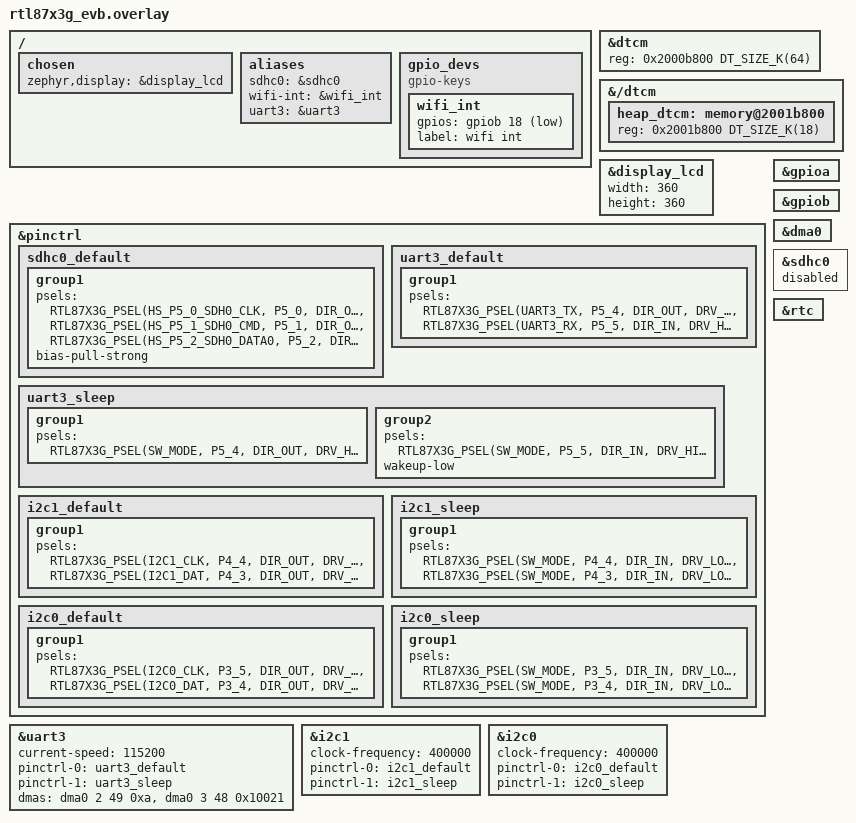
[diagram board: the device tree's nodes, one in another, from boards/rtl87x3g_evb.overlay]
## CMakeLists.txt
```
# SPDX-License-Identifier: Apache-2.0

cmake_minimum_required(VERSION 3.20.0)

#===========version generation===========
include(${CMAKE_CURRENT_SOURCE_DIR}/../../cmake/version_generate.cmake)
generate_version()
#===========version generation===========
#===========post build===========
# post build should be called before find_package
include(${CMAKE_CURRENT_SOURCE_DIR}/../../cmake/post_build.cmake)
# Extract bank name from snippet list (e.g. "flash_16M_bank0" -> "bank0") so
# `west build --snippet flash_16M_bank0/bank1` outputs to bin/<bank>/  (mirrors sample/ota).
set(RTK_BANK "")
foreach(snippet ${SNIPPET})
    if(snippet MATCHES "bank[0-9]+")
        string(REGEX MATCH "bank[0-9]+" RTK_BANK "${snippet}")
        break()
    endif()
endforeach()
if(RTK_BANK)
    # bank build -> bin/<bank>/app_<bank>.bin (+ _MP.bin)
    rtk_post_build(APP_NAME app BANK ${RTK_BANK})
else()
    # default (no snippet) -> bin/app.bin, unchanged
    rtk_post_build()
endif()
#===========post build===========

# FlashDB is pulled in as a West project; its module.yml declares kconfig-ext: True,
# so Zephyr automatically generates osource "$(ZEPHYR_FLASHDB_KCONFIG)".
# Point that variable at the empty Kconfig inside this application to avoid build errors.
set(ZEPHYR_FLASHDB_KCONFIG ${CMAKE_CURRENT_SOURCE_DIR}/port/flashdb/Kconfig)

find_package(Zephyr REQUIRED HINTS $ENV{ZEPHYR_BASE})
project(deskmate)

target_link_libraries(app PRIVATE realtek_display_driver_library)
target_link_libraries(app PRIVATE guiLib)

zephyr_compile_options(
    -Wno-unused-variable
    -Wno-maybe-uninitialized
    -Wno-double-promotion
    -Wno-stringop-truncation
    -Wno-unused-function
    -Wno-missing-braces
    -Wno-use-after-free
    -Wno-parentheses
    -Wno-address
    -Wno-format-overflow
    -Wno-overflow
    -Wno-char-subscripts
    -Wno-enum-compare
)

set(APP_TARGET_NAME app)

if(1) #set to 1 to enable or variable to for depnedency

    file(GLOB SOURCES "*.c" "*.cpp")
    file(GLOB HEADERS "*.h" "*.hpp")


    # Determine if we should create a library
    if((NOT HEADERS) AND (NOT SOURCES))
        message(STATUS "No source or header files found in ${CMAKE_CURRENT_SOURCE_DIR}.")
		target_include_directories(${APP_TARGET_NAME} PUBLIC ${CMAKE_CURRENT_SOURCE_DIR})
    endif()

    if(HEADERS AND (NOT SOURCES))
        target_include_directories(${APP_TARGET_NAME} PUBLIC ${CMAKE_CURRENT_SOURCE_DIR})
    endif()

    if(SOURCES AND (NOT HEADERS))
        target_sources(${APP_TARGET_NAME} PRIVATE ${SOURCES})
    endif()

    if(SOURCES AND HEADERS)
        target_sources(${APP_TARGET_NAME} PRIVATE ${SOURCES})
        target_include_directories(${APP_TARGET_NAME} PUBLIC ${CMAKE_CURRENT_SOURCE_DIR})
    endif()

    # Process subdirectories regardless
    file(GLOB SUBDIRS RELATIVE ${CMAKE_CURRENT_SOURCE_DIR} ${CMAKE_CURRENT_SOURCE_DIR}/*)

    foreach(subdir ${SUBDIRS})
        if(IS_DIRECTORY ${CMAKE_CURRENT_SOURCE_DIR}/${subdir})
            if(EXISTS ${CMAKE_CURRENT_SOURCE_DIR}/${subdir}/CMakeLists.txt)
                add_subdirectory(${subdir})
            else()
                message(STATUS "Skipping directory ${subdir} as it does not contain a CMakeLists.txt file.")
            endif()
        endif()
    endforeach()
endif()
```

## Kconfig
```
# Copyright (c) 2024, Realtek Semiconductor Corporation.
# SPDX-License-Identifier: Apache-2.0

menu "DeskMate Application"

config RTK_BT_BREDR
	bool "Enable Classic Bluetooth (BR/EDR) support"
	default n
	select REALTEK_SUBSYS_BTM
	select REALTEK_SUBSYS_SYSM
	select REALTEK_SUBSYS_REMOTE
	help
	  Enable Realtek Classic Bluetooth BR/EDR stack.
	  Activates BTM, SYSM, and Remote subsystems.

config RTK_BR_PROFILE_A2DP
	bool "Enable A2DP profile (Sink + Source)"
	depends on RTK_BT_BREDR
	default n

config RTK_BR_PROFILE_AVRCP
	bool "Enable AVRCP profile (CT + TG)"
	depends on RTK_BT_BREDR
	default n

config RTK_BR_PROFILE_HFP
	bool "Enable HFP profile (HF + AG)"
	depends on RTK_BT_BREDR
	default n

config RTK_BR_PROFILE_PAN
	bool "Enable PAN profile (PANU + NAP)"
	depends on RTK_BT_BREDR
	default n

config REALTEK_BUILD_EXAMPLE_EBADGE
    bool "Ebadge Widget Demo"
	default n

config HIGH_LEVEL_BOARD
    bool "High Level Board"
	default n

# External 8711 Wi-Fi chip over SPI: the WIFI_8711 switch app/protocol guards on,
# plus the AT-over-SPI transport it selects.  Turned on by the wifi snippet, which
# also carries the devicetree nodes the module binds to.
#
# One rsource where there were two.  The other was app/wifi_8711/Kconfig, the SPI
# SLAVE stack against custom 8711 firmware; that module is gone and WIFI_8711 moved
# in beside the transport it now selects.
rsource "app/spi_at_master/Kconfig"

endmenu

menu "Zephyr Kernel"
source "Kconfig.zephyr"
endmenu
```

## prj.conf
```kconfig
# App and platform logs use trace.h; do not enable the Zephyr LOG subsystem.
CONFIG_LOG=n
CONFIG_REALTEK_SUBSYS_BLE_MGR=y
CONFIG_RTK_BT_BREDR=y
CONFIG_DFU_NORMAL_OTA=y
CONFIG_RTK_BR_PROFILE_A2DP=y
CONFIG_RTK_BR_PROFILE_AVRCP=y
CONFIG_RTK_BR_PROFILE_HFP=y
CONFIG_REALTEK_SUBSYS_AUDIO=y
# PAN pulls in the IP stack and is unrelated to HFP/A2DP. The additional
# profile does not fit in the watch application partition with DSP enabled.
CONFIG_RTK_BR_PROFILE_PAN=n
CONFIG_SERIAL=y
CONFIG_CONSOLE=n
CONFIG_UART_CONSOLE=n
CONFIG_SHELL=n
CONFIG_SHELL_BACKEND_SERIAL=n
#start display config
CONFIG_REALTEK_HONEYGUI=y
# No current watch page uses H.264. Keeping the decoder linked leaves no room
# for the audio stack in the 1.5 MiB application partition.
CONFIG_REALTEK_H264_DECODER=n
CONFIG_REALTEK_H264BSD=n
# CONFIG_REALTEK_BUILD_EXAMPLE_IMAGE_WIDGET=y
# The Designer-generated smartwatch UI replaces the Real Canvas demo.
# Both use GUI_INIT_APP_EXPORT(app_init); enabling both at once redefines __honeygui_init_app_init.
CONFIG_REALTEK_BUILD_REAL_CANVAS=n
# CONFIG_REALTEK_BUILD_REAL_EARTH_3D=y

# HoneyGUI 2.x defaults optional widgets to y. The watch UI only uses the
# core, view, canvas, geometry, list, image and text widgets. Linking the
# remaining widgets overflows the watch application partition.
CONFIG_REALTEK_GUI_WIDGET_SVG=n
CONFIG_REALTEK_GUI_WIDGET_GIF=n
CONFIG_REALTEK_GUI_WIDGET_GLASS=n
CONFIG_REALTEK_GUI_WIDGET_VIDEO=n
CONFIG_REALTEK_GUI_WIDGET_LITE_VIDEO=n
CONFIG_REALTEK_GUI_WIDGET_STREAM=n
CONFIG_REALTEK_GUI_WIDGET_QBCODE=n
CONFIG_REALTEK_GUI_WIDGET_SOCCER=n
CONFIG_REALTEK_GUI_WIDGET_CARD_LIST=n
CONFIG_REALTEK_GUI_WIDGET_MENU_CELLULAR=n
# Console and log output remain enabled. HoneyGUI's separate letter-shell is
# not referenced by the generated watch UI and only consumes application
# partition space. The generated view headers include gui_list.h, so the list
# and canvas widgets remain enabled.
CONFIG_REALTEK_BUILD_LETTER_SHELL=n

CONFIG_DISPLAY=y
CONFIG_REALTEK_DISPLAY=y
CONFIG_REALTEK_DISPLAY_ENABLE_LCDC=y
CONFIG_REALTEK_DISPLAY_ENABLE_PPE=y
CONFIG_REALTEK_DISPLAY_ENABLE_IDU=y
CONFIG_REALTEK_DISPLAY_GUI_ACC=y
CONFIG_REALTEK_DISPLAY_ENABLE_JPU=y

# CONFIG_REALTEK_LCD_ST77916_360_360_QSPI is not set
CONFIG_REALTEK_LCD_AUTO_360_360_QSPI=y
CONFIG_REALTEK_TOUCH_CHSC6417_ZEPHYR=n
CONFIG_REALTEK_KEY_BUTTON_8773G_ZEPHYR=n
CONFIG_GPIO=y
CONFIG_GPIO_ENABLE_DISABLE_INTERRUPT=y
CONFIG_I2C=y
CONFIG_CPP=y
CONFIG_REQUIRES_FULL_LIBCPP=y
CONFIG_NEWLIB_LIBC=y
#start display config
CONFIG_SIZE_OPTIMIZATIONS_AGGRESSIVE=y
CONFIG_UART_ASYNC_API=y
CONFIG_SDHC=n
CONFIG_SDIO_STACK=n
CONFIG_HEAP_MEM_POOL_SIZE=2048
CONFIG_OSIF_TASK_MAX_COUNT=12

CONFIG_CBPRINTF_FP_SUPPORT=n
# The new upstream display/HoneyGUI code needs a smaller stack footprint to
# keep the fixed RAM region within budget. The main work still runs in the
# application and Bluetooth task stacks.
CONFIG_MAIN_STACK_SIZE=4096
CONFIG_IDLE_STACK_SIZE=1024
CONFIG_SYSTEM_WORKQUEUE_STACK_SIZE=768

# RTC (posix /dev/rtc0 + editor-level features)
CONFIG_RTC=y
CONFIG_RTC_RTL87X3G=y
CONFIG_RTC_ALARM=y
CONFIG_RTC_UPDATE=y
```

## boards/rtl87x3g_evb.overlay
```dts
/*
 * Copyright (c) 2024, Realtek Semiconductor Corporation. All rights reserved.
 */

#include <zephyr/dt-bindings/pinctrl/rtl87x3g-pinctrl.h>
#include <zephyr/dt-bindings/gpio/realtek-rtl87x3g-gpio.h>
#include <rtl87x3g-display-lcd.dtsi>

/ {
	chosen {
		zephyr,display = &display_lcd;
	};

};

/* HealthAlgorithm adds about 3 KiB of static RAM. Move 4 KiB from the
 * separate DTCM heap into the linked DTCM region. */
&dtcm {
	reg = <0x2000b800 DT_SIZE_K(64)>;
};

&{/dtcm} {
	/delete-node/ memory@2001a800;

	heap_dtcm: memory@2001b800 {
		device_type = "heap dtcm region";
		reg = <0x2001b800 DT_SIZE_K(18)>;
	};
};

&display_lcd {
	status = "okay";
	/* ST77916 360x360 QSPI: override dtsi default (480x272) */
	width = <360>;
	height = <360>;
};

&pinctrl {
	sdhc0_default: sdhc0_default {
		group1 {
			psels =
				<RTL87X3G_PSEL(HS_P5_0_SDH0_CLK,   P5_0, DIR_OUT, DRV_HIGH, PULL_UP)>,
				<RTL87X3G_PSEL(HS_P5_1_SDH0_CMD,   P5_1, DIR_OUT, DRV_HIGH, PULL_UP)>,
				<RTL87X3G_PSEL(HS_P5_2_SDH0_DATA0, P5_2, DIR_OUT, DRV_HIGH, PULL_UP)>;
			bias-pull-strong;
		};
	};

	uart3_default: uart3_default {
		group1 {
			psels =
				<RTL87X3G_PSEL(UART3_TX, P5_4, DIR_OUT, DRV_HIGH, PULL_UP)>,
				<RTL87X3G_PSEL(UART3_RX, P5_5, DIR_IN,  DRV_HIGH, PULL_UP)>;
		};
	};
	uart3_sleep: uart3_sleep {
		group1 {
			psels = <RTL87X3G_PSEL(SW_MODE, P5_4, DIR_OUT, DRV_HIGH, PULL_UP)>;
		};
		group2 {
			psels = <RTL87X3G_PSEL(SW_MODE, P5_5, DIR_IN, DRV_HIGH, PULL_UP)>;
			wakeup-low;
		};
	};

	i2c1_default: i2c1_default {
		group1 {
			psels =
				<RTL87X3G_PSEL(I2C1_CLK, P4_4, DIR_OUT, DRV_HIGH, PULL_NONE)>,
				<RTL87X3G_PSEL(I2C1_DAT, P4_3, DIR_OUT, DRV_HIGH, PULL_NONE)>;
		};
	};
	i2c1_sleep: i2c1_sleep {
		group1 {
			psels =
				<RTL87X3G_PSEL(SW_MODE, P4_4, DIR_IN, DRV_LOW, PULL_UP)>,
				<RTL87X3G_PSEL(SW_MODE, P4_3, DIR_IN, DRV_LOW, PULL_UP)>;
		};
	};

	/* I2C0 (Gsensor): SCL=P3_5, SDA=P3_4 */
	i2c0_default: i2c0_default {
		group1 {
			psels =
				<RTL87X3G_PSEL(I2C0_CLK, P3_5, DIR_OUT, DRV_HIGH, PULL_NONE)>,
				<RTL87X3G_PSEL(I2C0_DAT, P3_4, DIR_OUT, DRV_HIGH, PULL_NONE)>;
		};
	};
	i2c0_sleep: i2c0_sleep {
		group1 {
			psels =
				<RTL87X3G_PSEL(SW_MODE, P3_5, DIR_IN, DRV_LOW, PULL_UP)>,
				<RTL87X3G_PSEL(SW_MODE, P3_4, DIR_IN, DRV_LOW, PULL_UP)>;
		};
	};
};

&gpioa {
	status = "okay";
};

&gpiob {
	status = "okay";
};

&uart3 {
	status = "okay";
	current-speed = <115200>;
	pinctrl-0 = <&uart3_default>;
	pinctrl-1 = <&uart3_sleep>;
	pinctrl-names = "default", "sleep";
	dmas = <&dma0 2 49 0xa>, <&dma0 3 48 0x10021>;
	dma-names = "rx", "tx";
};

&dma0 {
	status = "okay";
};

&sdhc0 {
	/* MOY.M81023.01 has no SD socket. P5_0/P5_1/P5_2 are the display
	 * backlight, sensor rail enable and LCD reset controls instead. */
	status = "disabled";
};

/ {
	aliases {
		sdhc0 = &sdhc0;
		wifi-int = &wifi_int;
		uart3 = &uart3;
	};
	gpio_devs {
		compatible = "gpio-keys";
		wifi_int: wifi_int {
			gpios = <&gpiob 18 GPIO_ACTIVE_LOW>;  /* P5_3 */
			label = "wifi int";
		};
	};

};

&i2c1 {
	status = "okay";
	clock-frequency = <400000>;
	pinctrl-0 = <&i2c1_default>;
	pinctrl-1 = <&i2c1_sleep>;
	pinctrl-names = "default", "sleep";
};

&i2c0 {
	status = "okay";
	clock-frequency = <400000>;
	pinctrl-0 = <&i2c0_default>;
	pinctrl-1 = <&i2c0_sleep>;
	pinctrl-names = "default", "sleep";
};

&rtc {
	status = "okay";
};
```

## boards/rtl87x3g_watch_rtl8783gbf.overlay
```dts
#include <zephyr/dt-bindings/gpio/realtek-rtl87x3g-gpio.h>
#include <dt-bindings/pinctrl/rtl87x3g-pinctrl.h>

&uart3 {
	pinctrl-0 = <&uart3_default>;
	pinctrl-1 = <&uart3_sleep>;
	pinctrl-names = "default", "sleep";
	status = "okay";
	current-speed = <115200>;
	parity = "none";
	stop-bits = "1";
	data-bits = <8>;
	dmas = <&dma0 2 49 0xa>, <&dma0 3 48 0x10021>;
	dma-names = "rx", "tx";
};

&pinctrl {
	uart3_default: uart3_default {
		group1 {
			psels = <RTL87X3G_PSEL(UART3_TX, UART3_TX_PIN, DIR_OUT, DRV_HIGH, PULL_UP)>,
				<RTL87X3G_PSEL(UART3_RX, UART3_RX_PIN, DIR_IN, DRV_HIGH, PULL_UP)>,
				<RTL87X3G_PSEL(SW_MODE, UART3_MP_TX_PIN, DIR_OUT, DRV_HIGH, PULL_UP)>,
				<RTL87X3G_PSEL(SW_MODE, UART3_MP_RX_PIN, DIR_IN, DRV_HIGH, PULL_UP)>;
		};
	};

	uart3_mp: uart3_mp {
		group1 {
			psels = <RTL87X3G_PSEL(SW_MODE, UART3_TX_PIN, DIR_OUT, DRV_HIGH, PULL_UP)>,
				<RTL87X3G_PSEL(SW_MODE, UART3_RX_PIN, DIR_IN, DRV_HIGH, PULL_UP)>,
				<RTL87X3G_PSEL(UART3_TX, UART3_MP_TX_PIN, DIR_OUT, DRV_HIGH, PULL_UP)>,
				<RTL87X3G_PSEL(UART3_RX, UART3_MP_RX_PIN, DIR_IN, DRV_HIGH, PULL_UP)>;
		};
	};

	uart3_sleep: uart3_sleep {
		group1 {
			psels = <RTL87X3G_PSEL(SW_MODE, UART3_TX_PIN, DIR_OUT, DRV_HIGH, PULL_UP)>,
				<RTL87X3G_PSEL(SW_MODE, UART3_MP_TX_PIN, DIR_OUT, DRV_HIGH, PULL_UP)>;
		};

		group2 {
			psels = <RTL87X3G_PSEL(SW_MODE, UART3_RX_PIN, DIR_IN, DRV_HIGH, PULL_UP)>,
				<RTL87X3G_PSEL(SW_MODE, UART3_MP_RX_PIN, DIR_IN, DRV_HIGH, PULL_UP)>;
			wakeup-low;
		};
	};
};

/ {
	aliases {
		sdhc0 = &sdhc0;
		uart3 = &uart3;
		wifi-int = &wifi_int;
	};

	zephyr,user {
		uart3_mp_pin = <&uart3_mp>;
	};

	gpio_devs {
		compatible = "gpio-keys";

		wifi_int: wifi_int {
			gpios = <WIFI_INT_GPIO_PIN GPIO_ACTIVE_LOW>;
			label = "wifi int";
		};
	};
};
```

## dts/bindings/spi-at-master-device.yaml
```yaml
#
# Copyright (c) 2026, Realtek Semiconductor Corporation
#
# SPDX-License-Identifier: LicenseRef-Realtek-5-Clause
#

description: |
    The RTL8711FA as a slave device on our SPI bus.

    This child node exists only in the master configuration.  As slave we had no
    bus peer to describe, so the wifi_8711 overlay put status="okay" on
    spi0_slave and stopped there; as master the peer is a real device and its
    spi-max-frequency is what the controller is programmed to.

    That property is load-bearing rather than documentation: SPI_DT_SPEC_GET
    copies it into spi_config.frequency, and spi_rtl87x3g_configure() rejects
    anything above the parent node's max-bus-freq outright (-EINVAL, not a
    clamp).  25 MHz therefore only works under spi1_hs, which is rated 50 MHz --
    spi0/spi1/spi2 are all rated 20 MHz and would fail at bring-up.

    Consumed by app/spi_at_master/ via DT_NODELABEL(spi_at_master_device).

compatible: "spi-at-master-device"

include: [spi-device.yaml]
```

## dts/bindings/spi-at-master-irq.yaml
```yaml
#
# Copyright (c) 2026, Realtek Semiconductor Corporation
#
# SPDX-License-Identifier: LicenseRef-Realtek-5-Clause
#

description: |
    The two out-of-band handshake GPIOs of the RTL8773G <-> RTL8711FA SPI link
    in its MASTER configuration: we drive SCLK and CS, the 8711 is the slave.

    The pads are the same two the slave build used and their DIRECTIONS ARE
    SWAPPED.  That is the one mistake this binding exists to prevent, because an
    overlay copied from wifi_8711-irq compiles perfectly and then drives the
    wrong line the wrong way, with nothing catching it at build time:

                     wifi_8711-irq (slave)      THIS binding (master)
      P4_1 GPIOB8    b2w, our OUTPUT            s2m, our INPUT
      P2_7 GPIOA22   w2b, our INPUT             m2s, our OUTPUT

    The names are relative to whoever holds the master role, which is now us --
    hence m2s/s2m rather than b2w/w2b.  Do not mix the two vocabularies.

    Handshake, per the vendor reference example/atcmd_host/atcmd_host_spi:

      m2s  master -> slave REQUEST, our output.  Asserted (pad LOW) to tell the
           8711 "prepare to receive"; released (pad HIGH) once the slot has been
           clocked.  It is only a request -- it never starts a transfer by
           itself.
      s2m  slave -> master GO-AHEAD, our interrupt input.  The 8711 raises it
           when its DMA is armed, whether that is in answer to our m2s or
           because it has something of its own to send.  The rising edge is the
           go-ahead for BOTH directions, so it is the only edge we act on and
           the transport blocks on it before every transfer.

    Idle levels, which the polarity flags below must encode:
      m2s idles HIGH, asserted LOW   -> declare it GPIO_ACTIVE_LOW, so
                                        GPIO_OUTPUT_INACTIVE parks the pad high
      s2m idles LOW,  asserted HIGH  -> declare it GPIO_ACTIVE_HIGH

    Consumed by app/spi_at_master/ via DT_NODELABEL(spi_at_master_resources).

compatible: "spi-at-master-irq"

properties:
  m2s-gpios:
    type: phandle-array
    required: true
    description: |
      M2S / REQUEST: 8773 -> 8711, our push-pull output.  Active LOW, idles
      HIGH -- must carry GPIO_ACTIVE_LOW or the line is inverted in silence.
  s2m-gpios:
    type: phandle-array
    required: true
    description: |
      S2M / GO-AHEAD: 8711 -> 8773, our interrupt input.  Active high, idles
      low; a pull-down keeps a floating line from reading as a permanent
      go-ahead before the 8711 powers up.
```

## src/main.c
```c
/**
*********************24, Realtek Semiconductor Corporation. All rights reserved.
*****************************************************************************************
   * @file      main.c
   * @brief     Source file for display project, mainly used for initialize modules
   * @author    Luke
   * @date      2024-08-29
   * @version   v1.0
   **************************************************************************************
   * @attention
   * <h2><center>&copy; COPYRIGHT 2023 Realtek Semiconductor Corporation</center></h2>
   **************************************************************************************
  */

/*============================================================================*
 *                              Header Files
 *============================================================================*/

#include "trace.h"
#include "display_init.h"
#include "os_sched.h"





/* Non-Secure main. */
int main(void)
{
    DBG_DIRECT("Non-Secure World: main");

    display_system_clock_init();
    display_components_init();
    display_task_init();

    /* Start scheduler. */
    os_sched_start();
}
/*-----------------------------------------------------------*/
```

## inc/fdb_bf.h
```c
/*
 * Copyright (c) 2020, Armink, <armink.ztl@gmail.com>
 *
 * SPDX-License-Identifier: Apache-2.0
 */

/**
 * @file
 * @brief Big File (BF) extension public APIs.
 *
 * The Big File extension stores bulk data in a dedicated FAL data partition while
 * keeping a per-file directory entry inside a user-shared KVDB. Each directory
 * entry is a single KV whose name uses the reserved prefix FDB_BF_KEY_PREFIX, so a
 * file commit equals one atomic KV set. The data partition must live on a NOR flash
 * (write granularity == 1 bit) and is managed by a rotating allocator.
 */

#ifndef _FDB_BF_H_
#define _FDB_BF_H_

#include <stdint.h>
#include <stddef.h>
#include <stdbool.h>
#include <fdb_cfg.h>
#include <fdb_def.h>

#ifdef FDB_USING_BF

#ifndef FDB_USING_FAL_MODE
#error "The Big File extension (FDB_USING_BF) requires FDB_USING_FAL_MODE."
#endif

#include <fal.h>

#ifdef __cplusplus
extern "C" {
#endif

/* the reserved KV name prefix used by the directory entries */
#ifndef FDB_BF_KEY_PREFIX
#define FDB_BF_KEY_PREFIX            "bf/"
#endif

/* the max length (including the '\0') of a user file key, excluding the prefix */
#ifndef FDB_BF_KEY_MAX
#define FDB_BF_KEY_MAX               32
#endif

/* the max number of files that can be opened/created at the same time */
#ifndef FDB_BF_MAX_OPEN_HANDLES
#define FDB_BF_MAX_OPEN_HANDLES      4
#endif

/* the max number of files the allocator can track when searching for free space */
#ifndef FDB_BF_MAX_ENTRIES
#define FDB_BF_MAX_ENTRIES           32
#endif

/* directory entry flag bits (32 bit) */
#define FDB_BF_FLAG_CRC_VALID        0x00000001U     /**< data_crc field holds a valid CRC32 of the data */

/**
 * Big File directory entry. Stored as the value of one KVDB KV (24 bytes).
 */
struct fdb_bf_dirent
{
    uint32_t offset;        /**< data offset relative to the data partition start */
    uint32_t capacity;      /**< allocated capacity, aligned to flash block size */
    uint32_t size;          /**< valid data length (<= capacity) */
    uint32_t data_crc;      /**< CRC32 of data range [offset, offset + size), valid when FDB_BF_FLAG_CRC_VALID set */
    uint32_t flags;         /**< flag bits, @see FDB_BF_FLAG_* */
    uint32_t reserved;      /**< reserved for future use, set to 0 */
};
typedef struct fdb_bf_dirent *fdb_bf_dirent_t;

/**
 * Big File open/write handle.
 */
struct fdb_bf_file
{
    struct fdb_bf *db;                 /**< owner BF object */
    bool      in_use;                  /**< handle slot is allocated */
    char      key[FDB_BF_KEY_MAX];     /**< user file key (without prefix) */
    uint32_t  offset;                  /**< data offset in the data partition */
    uint32_t  capacity;                /**< allocated capacity */
    uint32_t  size;                    /**< current valid data length */
};
typedef struct fdb_bf_file *fdb_bf_file_t;

/**
 * Big File database object.
 */
struct fdb_bf
{
    fdb_kvdb_t
    dir_kvdb;                          /**< user-shared KVDB holding the directory entries */
    const struct fal_partition *data_part;         /**< data partition */
    const struct fal_flash_dev *data_flash;        /**< flash device of the data partition */
    uint32_t
    blk_size;                          /**< erase block size of the data flash (allocation unit) */
    uint32_t    data_size;                         /**< data partition length in bytes */
    uint32_t    write_cursor;                      /**< rotating allocation cursor, rebuilt at init */
    struct fdb_bf_file handles[FDB_BF_MAX_OPEN_HANDLES];
    void       *user_data;
    bool        inited;                            /**< initialized successfully */
};
typedef struct fdb_bf *fdb_bf_t;

/**
 * The callback used by fdb_bf_foreach().
 *
 * @param key the user file key (without prefix)
 * @param ent the directory entry
 * @param xip_addr the absolute (memory-mapped/XIP) flash address of the file data
 * @param arg the user argument passed to fdb_bf_foreach()
 *
 * @return return true to stop the iteration, false to continue
 */
typedef bool (*fdb_bf_iter_cb)(const char *key, const struct fdb_bf_dirent *ent, uint32_t xip_addr,
                               void *arg);

/**
 * Big File space usage. Filled in by fdb_bf_space().
 *
 * The allocator only ever hands out a *contiguous* block-aligned run, so
 * `largest_free` -- not `free_size` -- decides whether an fdb_bf_create() of a
 * given size can succeed. The two differ once the partition is fragmented.
 */
struct fdb_bf_space
{
    uint32_t total_size;      /**< data partition length, == db->data_size */
    uint32_t used_size;       /**< sum of every entry's allocated capacity */
    uint32_t free_size;       /**< total_size - used_size, possibly fragmented */
    uint32_t largest_free;    /**< biggest contiguous free run; the usable limit */
    uint32_t valid_size;      /**< sum of every entry's valid data length */
    uint32_t file_count;      /**< number of committed big files */
    uint32_t blk_size;        /**< allocation unit (erase block size) */
    bool     truncated;       /**< true: > FDB_BF_MAX_ENTRIES files, figures are partial */
};

/* lifecycle */
fdb_err_t fdb_bf_init(fdb_bf_t db, fdb_kvdb_t dir_kvdb, const char *data_part_name,
                      void *user_data);
fdb_err_t fdb_bf_deinit(fdb_bf_t db);

/* write: create -> append... -> commit(data_crc) / abort
 *
 * fdb_bf_commit(file, NULL)       -- commit without data CRC
 * fdb_bf_commit(file, &crc_val)   -- commit and store caller-computed CRC32
 *                                    (sets FDB_BF_FLAG_CRC_VALID in flags)
 *
 * The caller is responsible for accumulating the CRC across fdb_bf_append
 * calls using any CRC32 implementation they prefer.
 */
fdb_err_t fdb_bf_create(fdb_bf_t db, const char *key, size_t max_size, fdb_bf_file_t *out);
fdb_err_t fdb_bf_append(fdb_bf_file_t file, const void *buf, size_t len);
fdb_err_t fdb_bf_commit(fdb_bf_file_t file, const uint32_t *data_crc);
fdb_err_t fdb_bf_abort(fdb_bf_file_t file);

/* manage */
fdb_err_t fdb_bf_delete(fdb_bf_t db, const char *key);
fdb_err_t fdb_bf_delete_by_addr(fdb_bf_t db, uint32_t addr);

/**
 * How much of the data partition fdb_bf_reset() erases.
 *
 * This is a choice about ERASE COST, not about correctness: either way every
 * directory entry is dropped, so either way the files are gone and every figure
 * the API reports falls back to empty.  fdb_bf_create() erases each range before
 * it hands it out, so nothing downstream depends on the partition having been
 * pre-erased.
 *
 * Spelled as an enum rather than a bool because `fdb_bf_reset(db, true, &n)` at
 * a call site says nothing about what is true.
 */
typedef enum
{
    /**
     * Drop the directory only.  Milliseconds: one KV delete per file, and a KV
     * delete just flips a status field in place.
     *
     * The old bytes stay on flash until something allocates over them.  They are
     * unreachable through this API -- no entry names them -- but they are still
     * readable by anything that walks the raw partition.
     */
    FDB_BF_RESET_DIR_ONLY = 0,

    /**
     * Also erase the whole data partition, so no remnant of the old files is
     * readable afterwards.
     *
     * SECONDS, and it scales with the partition, not with how much of it is in
     * use: one sector erase per blk_size of the WHOLE partition.  On the eBadge's
     * 5 MB bf_data at 4 KB sectors that is 1280 erases, and it costs the same
     * whether one file was stored or thirty.  Do not put this on a path a user
     * waits on unless the remnants matter.
     */
    FDB_BF_RESET_ERASE_DATA,
} fdb_bf_reset_mode_t;

/**
 * Factory-reset the Big File area: drop every directory entry, and optionally
 * erase the data partition too.
 *
 * Only KVs carrying the reserved FDB_BF_KEY_PREFIX are removed -- the directory
 * KVDB is shared with the application, and its ordinary KVs are left untouched.
 * (This is why fdb_kv_set_default() is NOT the right tool here: it would wipe
 * the application's own settings along with the file directory.)
 *
 * Every "record" a caller can observe -- file_count, used_size, valid_size, the
 * allocator's write cursor -- is *derived* from the directory entries on each
 * query, never stored, so all of them fall back to empty as a consequence of
 * clearing the directory. There is no separate counter to reset.
 *
 * WHICH MODE TO PASS.  FDB_BF_RESET_DIR_ONLY unless you specifically need the old
 * bytes gone: the erase is the entire cost of this call (milliseconds against
 * seconds) and it buys nothing the directory clear has not already bought.  See
 * fdb_bf_reset_mode_t.
 *
 * Order is deliberate when erasing: the directory is cleared *before* the payload.
 * A power loss during the (multi-second) erase then leaves entries gone and data
 * partly erased, which is consistent. The reverse order would leave entries
 * pointing at erased bytes, i.e. files that exist but read as 0xFF.
 *
 * @param db          the BF object
 * @param mode        FDB_BF_RESET_DIR_ONLY or FDB_BF_RESET_ERASE_DATA
 * @param out_removed optional, receives the number of entries deleted; may be
 *                    NULL. It is filled in even when the erase step later fails.
 *
 * @return FDB_NO_ERR on success;
 *         FDB_BUSY if a write session (fdb_bf_create) is still open -- commit or
 *         abort it first, since resetting under it would strand its handle;
 *         FDB_ERASE_ERR if the payload erase failed (directory is already empty,
 *         so the files are gone regardless; only stale bytes survive).
 */
fdb_err_t fdb_bf_reset(fdb_bf_t db, fdb_bf_reset_mode_t mode, uint32_t *out_removed);
bool      fdb_bf_exists(fdb_bf_t db, const char *key);
fdb_err_t fdb_bf_stat(fdb_bf_t db, const char *key, struct fdb_bf_dirent *out);
fdb_err_t fdb_bf_foreach(fdb_bf_t db, fdb_bf_iter_cb cb, void *arg);
fdb_err_t fdb_bf_get_addr(fdb_bf_t db, const char *key, uint32_t *out_addr, size_t *out_size);

/* space accounting
 *
 * fdb_bf_space()      -- full report, one pass over the directory entries
 * fdb_bf_free_size()  -- shorthand for the number that actually gates a create:
 *                        the largest contiguous free run, 0 on error
 */
fdb_err_t fdb_bf_space(fdb_bf_t db, struct fdb_bf_space *out);
uint32_t  fdb_bf_free_size(fdb_bf_t db);

#ifdef __cplusplus
}
#endif

#endif /* FDB_USING_BF */

#endif /* _FDB_BF_H_ */
```

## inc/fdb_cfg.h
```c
/*
 * Copyright (c) 2022, kaans, <https://github.com/kaans>
 *
 * SPDX-License-Identifier: Apache-2.0
 */

/**
 * @file
 * @brief configuration file
 */

#ifndef _FDB_CFG_H_
#define _FDB_CFG_H_

/* using KVDB feature */
#define FDB_USING_KVDB

#ifdef FDB_USING_KVDB
/* Auto update KV to latest default when current KVDB version number is changed. @see fdb_kvdb.ver_num */
/* #define FDB_KV_AUTO_UPDATE */

#define FDB_USING_BF
#endif

/* using TSDB (Time series database) feature */
#define FDB_USING_TSDB

/* Using FAL storage mode */
#define FDB_USING_FAL_MODE

/* the flash write granularity, unit: bit
 * only support 1(nor flash)/ 8(stm32f2/f4)/ 32(stm32f1) */
#define FDB_WRITE_GRAN 1 /* @note you must define it for a value */

/* MCU Endian Configuration, default is Little Endian Order. */
/* #define FDB_BIG_ENDIAN  */

/* log print macro using ESP_LOG.
 * Need to include esp_log.h when setting FDB_PRINT to ESP_LOGI().
 * default EF_PRINT macro is printf() */
//#include <esp_log.h>
//#define FDB_PRINT(...) ESP_LOGI("fdb", __VA_ARGS__)

/* print debug information */
#define FDB_DEBUG_ENABLE

#endif /* _FDB_CFG_H_ */
```

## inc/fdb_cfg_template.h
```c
/*
 * Copyright (c) 2020, Armink, <armink.ztl@gmail.com>
 *
 * SPDX-License-Identifier: Apache-2.0
 */

/**
 * @file
 * @brief configuration template file. You need to rename the file to "fbd_cfg.h" and modify the configuration items in it to suit your use.
 */

#ifndef _FDB_CFG_H_
#define _FDB_CFG_H_

/* using KVDB feature */
#define FDB_USING_KVDB

#ifdef FDB_USING_KVDB
/* Auto update KV to latest default when current KVDB version number is changed. @see fdb_kvdb.ver_num */
/* #define FDB_KV_AUTO_UPDATE */
#endif

/* using TSDB (Time series database) feature */
#define FDB_USING_TSDB

/* Use fixed-size blobs in TSDB to save flash overhead (8 bytes per entry).
 * Define this to the fixed blob size in bytes when all TSL entries are the same size.
 * Ideal for logging fixed-size sensor data (e.g., float + timestamp).
 * Warning: If defined will be incompatible with variable blob flash store or if fixed blob size is later changed */
/* #define FDB_TSDB_FIXED_BLOB_SIZE 4 */

/* Using FAL storage mode */
#define FDB_USING_FAL_MODE

#ifdef FDB_USING_FAL_MODE
/* the flash write granularity, unit: bit
 * only support 1(nor flash)/ 8(stm32f2/f4)/ 32(stm32f1)/ 64(stm32f7)/ 128(stm32h5)/ 256(stm32h7) */
#define FDB_WRITE_GRAN                /* @note you must define it for a value */
#endif

/* Using file storage mode by LIBC file API, like fopen/fread/fwrte/fclose */
/* #define FDB_USING_FILE_LIBC_MODE */

/* Using file storage mode by POSIX file API, like open/read/write/close */
/* #define FDB_USING_FILE_POSIX_MODE */

/* Using the Big File (BF) extension.
 * Requires FDB_USING_FAL_MODE and a NOR flash data partition (write_gran == 1).
 * A user-shared KVDB holds 24-byte directory entries under the "bf/" prefix, while
 * bulk data lives in a dedicated FAL partition managed by a rotating allocator. */
/* #define FDB_USING_BF */

#ifdef FDB_USING_BF
/* KV name prefix reserved for Big File directory entries. Default: "bf/" */
/* #define FDB_BF_KEY_PREFIX           "bf/" */

/* max user file key length including the terminating '\0'. Default: 32 */
/* #define FDB_BF_KEY_MAX              32 */

/* max number of concurrently open/writing file handles. Default: 4 */
/* #define FDB_BF_MAX_OPEN_HANDLES     4 */

/* max number of files tracked by the allocator (occupancy table size). Default: 32 */
/* #define FDB_BF_MAX_ENTRIES          32 */
#endif

/* MCU Endian Configuration, default is Little Endian Order. */
/* #define FDB_BIG_ENDIAN */

/* log print macro. default EF_PRINT macro is printf() */
/* #define FDB_PRINT(...)              my_printf(__VA_ARGS__) */

/* print debug information */
#define FDB_DEBUG_ENABLE

#endif /* _FDB_CFG_H_ */
```

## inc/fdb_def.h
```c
/*
 * Copyright (c) 2020-2023, Armink, <armink.ztl@gmail.com>
 *
 * SPDX-License-Identifier: Apache-2.0
 */

/**
 * @file
 * @brief Public definition.
 */

#ifndef _FDB_DEF_H_
#define _FDB_DEF_H_

#ifdef FDB_USING_NATIVE_ASSERT
#include <assert.h>
#endif

#ifdef __cplusplus
extern "C" {
#endif

/* software version number */
#define FDB_SW_VERSION                 "2.2.99"
#define FDB_SW_VERSION_NUM             0x20299

/* the KV max name length must less then it */
#ifndef FDB_KV_NAME_MAX
#define FDB_KV_NAME_MAX                64
#endif

/* the KV cache table size, it will improve KV search speed when using cache */
#ifndef FDB_KV_CACHE_TABLE_SIZE
#define FDB_KV_CACHE_TABLE_SIZE        64
#endif

/* the sector cache table size, it will improve KV save speed when using cache */
#ifndef FDB_SECTOR_CACHE_TABLE_SIZE
#define FDB_SECTOR_CACHE_TABLE_SIZE    8
#endif

#if (FDB_KV_CACHE_TABLE_SIZE > 0) && (FDB_SECTOR_CACHE_TABLE_SIZE > 0)
#define FDB_KV_USING_CACHE
#endif

#if defined(FDB_USING_FILE_LIBC_MODE) || defined(FDB_USING_FILE_POSIX_MODE)
#define FDB_USING_FILE_MODE
#endif

/* the file cache table size, it will improve GC speed in file mode when using cache */
#ifndef FDB_FILE_CACHE_TABLE_SIZE
#define FDB_FILE_CACHE_TABLE_SIZE    2
#endif

#ifndef FDB_WRITE_GRAN
#define FDB_WRITE_GRAN 1
#endif

/* log function. default FDB_PRINT macro is printf() */
#ifndef FDB_PRINT
// #define FDB_PRINT(...)                 printf(__VA_ARGS__)
#define FDB_PRINT(...) 
#endif
#define FDB_LOG_PREFIX1()              FDB_PRINT("[FlashDB]" FDB_LOG_TAG)
#define FDB_LOG_PREFIX2()              FDB_PRINT(" ")
#define FDB_LOG_PREFIX()               FDB_LOG_PREFIX1();FDB_LOG_PREFIX2()
#ifdef FDB_DEBUG_ENABLE
#define FDB_DEBUG(...)                 FDB_LOG_PREFIX();FDB_PRINT("(%s:%d) ", __FILE__, __LINE__);FDB_PRINT(__VA_ARGS__)
#else
#define FDB_DEBUG(...)
#endif
/* routine print function. Must be implement by user. */
#define FDB_INFO(...)                  FDB_LOG_PREFIX();FDB_PRINT(__VA_ARGS__)
/* assert for developer. */
#ifdef FDB_USING_NATIVE_ASSERT
#define FDB_ASSERT(EXPR)               assert(EXPR);
#else
#ifndef FDB_ASSERT
#define FDB_ASSERT(EXPR)                                                      \
if (!(EXPR))                                                                  \
{                                                                             \
    FDB_INFO("(%s) has assert failed at %s.\n", #EXPR, __func__);             \
    while (1);                                                                \
}
#endif /* FDB_ASSERT */
#endif /* FDB_USING_NATIVE_ASSERT */

#define FDB_KVDB_CTRL_SET_SEC_SIZE     0x00             /**< set sector size control command, this change MUST before database initialization */
#define FDB_KVDB_CTRL_GET_SEC_SIZE     0x01             /**< get sector size control command */
#define FDB_KVDB_CTRL_SET_LOCK         0x02             /**< set lock function control command */
#define FDB_KVDB_CTRL_SET_UNLOCK       0x03             /**< set unlock function control command */
#define FDB_KVDB_CTRL_SET_FILE_MODE    0x09             /**< set file mode control command, this change MUST before database initialization */
#define FDB_KVDB_CTRL_SET_MAX_SIZE     0x0A             /**< set database max size in file mode control command, this change MUST before database initialization */
#define FDB_KVDB_CTRL_SET_NOT_FORMAT   0x0B             /**< set database NOT format mode control command, this change MUST before database initialization */
#define FDB_KVDB_CTRL_SET_RESERVED_PREFIX 0x0C          /**< set the reserved KV name prefix; KVs using this prefix are rejected by the public set/del API (used by the Big File extension), this change MUST after database initialization */

#define FDB_TSDB_CTRL_SET_SEC_SIZE     0x00             /**< set sector size control command, this change MUST before database initialization */
#define FDB_TSDB_CTRL_GET_SEC_SIZE     0x01             /**< get sector size control command */
#define FDB_TSDB_CTRL_SET_LOCK         0x02             /**< set lock function control command */
#define FDB_TSDB_CTRL_SET_UNLOCK       0x03             /**< set unlock function control command */
#define FDB_TSDB_CTRL_SET_ROLLOVER     0x04             /**< set rollover control command, this change MUST after database initialization */
#define FDB_TSDB_CTRL_GET_ROLLOVER     0x05             /**< get rollover control command */
#define FDB_TSDB_CTRL_GET_LAST_TIME    0x06             /**< get last save time control command */
#define FDB_TSDB_CTRL_SET_FILE_MODE    0x09             /**< set file mode control command, this change MUST before database initialization */
#define FDB_TSDB_CTRL_SET_MAX_SIZE     0x0A             /**< set database max size in file mode control command, this change MUST before database initialization */
#define FDB_TSDB_CTRL_SET_NOT_FORMAT   0x0B             /**< set database NOT formatable mode control command, this change MUST before database initialization */

#ifdef FDB_USING_TIMESTAMP_64BIT
    typedef int64_t fdb_time_t;
#else
    typedef int32_t fdb_time_t;
#endif /* FDB_USING_TIMESTAMP_64BIT */

typedef fdb_time_t (*fdb_get_time)(void);

struct fdb_default_kv_node {
    char *key;
    void *value;
    size_t value_len;
};

struct fdb_default_kv {
    struct fdb_default_kv_node *kvs;
    size_t num;
};

/* error code */
typedef enum {
    FDB_NO_ERR,
    FDB_ERASE_ERR,
    FDB_READ_ERR,
    FDB_WRITE_ERR,
    FDB_PART_NOT_FOUND,
    FDB_KV_NAME_ERR,
    FDB_KV_NAME_EXIST,
    FDB_SAVED_FULL,
    FDB_INIT_FAILED,
    FDB_NOT_FOUND,                                /**< the target (KV / Big File / address) is not found */
    FDB_NO_SPACE,                                 /**< no enough space for the operation */
    FDB_UNSUPPORTED,                              /**< the operation is not supported on current storage medium */
    FDB_BUSY,                                     /**< no free resource (e.g. Big File open handle) */
    FDB_INVALID_PARAM,                            /**< invalid parameter */
} fdb_err_t;

enum fdb_kv_status {
    FDB_KV_UNUSED,
    FDB_KV_PRE_WRITE,
    FDB_KV_WRITE,
    FDB_KV_PRE_DELETE,
    FDB_KV_DELETED,
    FDB_KV_ERR_HDR,
#define FDB_KV_STATUS_NUM                        6
};
typedef enum fdb_kv_status fdb_kv_status_t;

enum fdb_tsl_status {
    FDB_TSL_UNUSED,
    FDB_TSL_PRE_WRITE,
    FDB_TSL_WRITE,
    FDB_TSL_USER_STATUS1,
    FDB_TSL_DELETED,
    FDB_TSL_USER_STATUS2,
#define FDB_TSL_STATUS_NUM                       6
};
typedef enum fdb_tsl_status fdb_tsl_status_t;

/* key-value node object */
struct fdb_kv {
    fdb_kv_status_t status;                      /**< node status, @see fdb_kv_status_t */
    bool crc_is_ok;                              /**< node CRC32 check is OK */
    uint8_t name_len;                            /**< name length */
    uint32_t magic;                              /**< magic word(`K`, `V`, `4`, `0`) */
    uint32_t len;                                /**< node total length (header + name + value), must align by FDB_WRITE_GRAN */
    uint32_t value_len;                          /**< value length */
    char name[FDB_KV_NAME_MAX];                  /**< name */
    struct {
        uint32_t start;                          /**< node start address */
        uint32_t value;                          /**< value start address */
    } addr;
};
typedef struct fdb_kv *fdb_kv_t;

struct fdb_kv_iterator {
    struct fdb_kv curr_kv;                       /**< Current KV we get from the iterator */
    uint32_t iterated_cnt;                       /**< How many KVs have we iterated already */
    size_t iterated_obj_bytes;                   /**< Total storage size of KVs we have iterated. */
    size_t iterated_value_bytes;                 /**< Total value size of KVs we have iterated. */
    uint32_t sector_addr;                        /**< Current sector address we're iterating. DO NOT touch it. */
    uint32_t traversed_len;                      /**< Traversed sector total length. */
};
typedef struct fdb_kv_iterator *fdb_kv_iterator_t;

/* time series log node object */
struct fdb_tsl {
    fdb_tsl_status_t status;                     /**< node status, @see fdb_log_status_t */
    fdb_time_t time;                             /**< node timestamp */
    uint32_t log_len;                            /**< log length, must align by FDB_WRITE_GRAN */
    struct {
        uint32_t index;                          /**< node index address */
        uint32_t log;                            /**< log data address */
    } addr;
};
typedef struct fdb_tsl *fdb_tsl_t;
typedef bool (*fdb_tsl_cb)(fdb_tsl_t tsl, void *arg);

typedef enum {
    FDB_DB_TYPE_KV,
    FDB_DB_TYPE_TS,
} fdb_db_type;

/* the flash sector store status */
enum fdb_sector_store_status {
    FDB_SECTOR_STORE_UNUSED,
    FDB_SECTOR_STORE_EMPTY,
    FDB_SECTOR_STORE_USING,
    FDB_SECTOR_STORE_FULL,
#define FDB_SECTOR_STORE_STATUS_NUM              4
};
typedef enum fdb_sector_store_status fdb_sector_store_status_t;

/* the flash sector dirty status */
enum fdb_sector_dirty_status {
    FDB_SECTOR_DIRTY_UNUSED,
    FDB_SECTOR_DIRTY_FALSE,
    FDB_SECTOR_DIRTY_TRUE,
    FDB_SECTOR_DIRTY_GC,
#define FDB_SECTOR_DIRTY_STATUS_NUM              4
};
typedef enum fdb_sector_dirty_status fdb_sector_dirty_status_t;

/* KVDB section information */
struct kvdb_sec_info {
    bool check_ok;                               /**< sector header check is OK */
    struct {
        fdb_sector_store_status_t store;         /**< sector store status @see fdb_sector_store_status_t */
        fdb_sector_dirty_status_t dirty;         /**< sector dirty status @see sector_dirty_status_t */
    } status;
    uint32_t addr;                               /**< sector start address */
    uint32_t magic;                              /**< magic word(`E`, `F`, `4`, `0`) */
    uint32_t combined;                           /**< the combined next sector number, 0xFFFFFFFF: not combined */
    size_t remain;                               /**< remain size */
    uint32_t empty_kv;                           /**< the next empty KV node start address */
};
typedef struct kvdb_sec_info *kv_sec_info_t;

/* TSDB section information */
struct tsdb_sec_info {
    bool check_ok;                               /**< sector header check is OK */
    fdb_sector_store_status_t status;            /**< sector store status @see fdb_sector_store_status_t */
    uint32_t addr;                               /**< sector start address */
    uint32_t magic;                              /**< magic word(`T`, `S`, `L`, `0`) */
    fdb_time_t start_time;                       /**< the first start node's timestamp, 0xFFFFFFFF: unused */
    fdb_time_t end_time;                         /**< the last end node's timestamp, 0xFFFFFFFF: unused */
    uint32_t end_idx;                            /**< the last end node's index, 0xFFFFFFFF: unused */
    fdb_tsl_status_t end_info_stat[2];           /**< the last end node's info status */
    size_t remain;                               /**< remain size */
    uint32_t empty_idx;                          /**< the next empty node index address */
    uint32_t empty_data;                         /**< the next empty node's data end address */
};
typedef struct tsdb_sec_info *tsdb_sec_info_t;

struct kv_cache_node {
    uint16_t name_crc;                           /**< KV name's CRC32 low 16bit value */
    uint16_t active;                             /**< KV node access active degree */
    uint32_t addr;                               /**< KV node address */
};
typedef struct kv_cache_node *kv_cache_node_t;

/* database structure */
typedef struct fdb_db *fdb_db_t;
struct fdb_db {
    const char *name;                            /**< database name */
    fdb_db_type type;                            /**< database type */
    union {
#ifdef FDB_USING_FAL_MODE
        const struct fal_partition *part;        /**< flash partition for saving database */
#endif
#ifdef FDB_USING_FILE_MODE
        const char *dir;                         /**< directory path for saving database */
#endif
    } storage;
    uint32_t sec_size;                           /**< flash section size. It's a multiple of block size */
    uint32_t max_size;                           /**< database max size. It's a multiple of section size */
    uint32_t oldest_addr;                        /**< the oldest sector start address */
    bool init_ok;                                /**< initialized successfully */
    bool file_mode;                              /**< is file mode, default is false */
    bool not_formatable;                         /**< is can NOT be formated mode, default is false */
#ifdef FDB_USING_FILE_MODE
    uint32_t cur_file_sec[FDB_FILE_CACHE_TABLE_SIZE];/**< last operate sector address  */
#if defined(FDB_USING_FILE_POSIX_MODE)
    int cur_file[FDB_FILE_CACHE_TABLE_SIZE];     /**< current file object */
#elif defined(FDB_USING_FILE_LIBC_MODE)
    FILE *cur_file[FDB_FILE_CACHE_TABLE_SIZE];   /**< current file object */
#endif /* FDB_USING_FILE_MODE */
    uint32_t cur_sec;                            /**< current operate sector address  */
#endif
    void (*lock)(fdb_db_t db);                   /**< lock the database operate */
    void (*unlock)(fdb_db_t db);                 /**< unlock the database operate */

    void *user_data;
};

/* KVDB structure */
struct fdb_kvdb {
    struct fdb_db parent;                        /**< inherit from fdb_db */
    struct fdb_default_kv default_kvs;           /**< default KV */
    bool gc_request;                             /**< request a GC check */
    bool in_recovery_check;                      /**< is in recovery check status when first reboot */
    struct fdb_kv cur_kv;
    struct kvdb_sec_info cur_sector;
    bool last_is_complete_del;
    const char *reserved_prefix;                 /**< reserved KV name prefix set by FDB_KVDB_CTRL_SET_RESERVED_PREFIX; NULL means no reservation */

#ifdef FDB_KV_USING_CACHE
    /* KV cache table */
    struct kv_cache_node kv_cache_table[FDB_KV_CACHE_TABLE_SIZE];
    /* sector cache table, it caching the sector info which status is current using */
    struct kvdb_sec_info sector_cache_table[FDB_SECTOR_CACHE_TABLE_SIZE];
#endif /* FDB_KV_USING_CACHE */

#ifdef FDB_KV_AUTO_UPDATE
    uint32_t ver_num;                            /**< setting version number for update */
#endif

    void *user_data;
};
typedef struct fdb_kvdb *fdb_kvdb_t;

/* TSDB structure */
struct fdb_tsdb {
    struct fdb_db parent;                        /**< inherit from fdb_db */
    struct tsdb_sec_info cur_sec;                /**< current using sector */
    fdb_time_t last_time;                        /**< last TSL timestamp */
    fdb_get_time get_time;                       /**< the current timestamp get function */
    size_t max_len;                              /**< the maximum length of each log */
    bool rollover;                               /**< the oldest data will rollover by newest data, default is true */

    void *user_data;
};
typedef struct fdb_tsdb *fdb_tsdb_t;

/* blob structure */
struct fdb_blob {
    void *buf;                                   /**< blob data buffer */
    size_t size;                                 /**< blob data buffer size */
    struct {
        uint32_t meta_addr;                      /**< saved KV or TSL index address */
        uint32_t addr;                           /**< blob data saved address */
        size_t len;                              /**< blob data saved length */
    } saved;
};
typedef struct fdb_blob *fdb_blob_t;

#ifdef __cplusplus
}
#endif

#endif /* _FDB_DEF_H_ */
```

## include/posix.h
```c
#ifndef POSIX_H
#define POSIX_H

/* ================================================================
 * POSIX device abstraction layer — unified entry point
 *
 * Usage:
 *   #include "posix.h"
 *
 *   Include the ioctl headers for the peripherals you need:
 *   #include "ioctls/posix_ioctl_uart.h"
 *
 * Switching chip or OS requires no change to this file,
 * only replacing the backend implementation under port/
 * ================================================================ */

#include "posix_types.h"
#include "posix_device.h"

/* ioctl headers are included on demand, not pulled in by posix.h,
 * because not every project uses all 6 peripheral types
 *
 * Recommended: include what you need in your project's device_cfg.h:
 *
 *   #include "posix.h"
 *   #include "ioctls/posix_ioctl_uart.h"
 *   #include "ioctls/posix_ioctl_spi.h"
 *   // ... other peripherals you need
 */

#endif /* POSIX_H */
```

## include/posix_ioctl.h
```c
#ifndef POSIX_IOCTL_H
#define POSIX_IOCTL_H

#include "posix_types.h"

/* ================================================================
 * ioctl cmd encoding scheme
 *
 * Encoding rules (similar to Linux, but simplified for embedded environments):
 *
 *   high bits                      low bits
 *   +----------------+-----------+
 *   |  magic (8 bit) | nr (8 bit) |
 *   +----------------+-----------+
 *
 * magic: device type identifier, one per device type
 * nr:    command sequence number, unique within a device type
 *
 * Macros:
 *   POSIX_IOC(magic, nr)        - build cmd
 *   POSIX_IOC_MAGIC(cmd)        - extract device type
 *   POSIX_IOC_NR(cmd)           - extract command number
 *
 * magic values are defined by POSIX_DEVICE_MAGIC_XXX in posix_device.h
 * ================================================================ */

#define POSIX_IOC(magic, nr)     ((int)((((magic) & 0xFF) << 8) | ((nr) & 0xFF)))
#define POSIX_IOC_MAGIC(cmd)     (((cmd) >> 8) & 0xFF)
#define POSIX_IOC_NR(cmd)        ((cmd) & 0xFF)

#endif /* POSIX_IOCTL_H */
```
